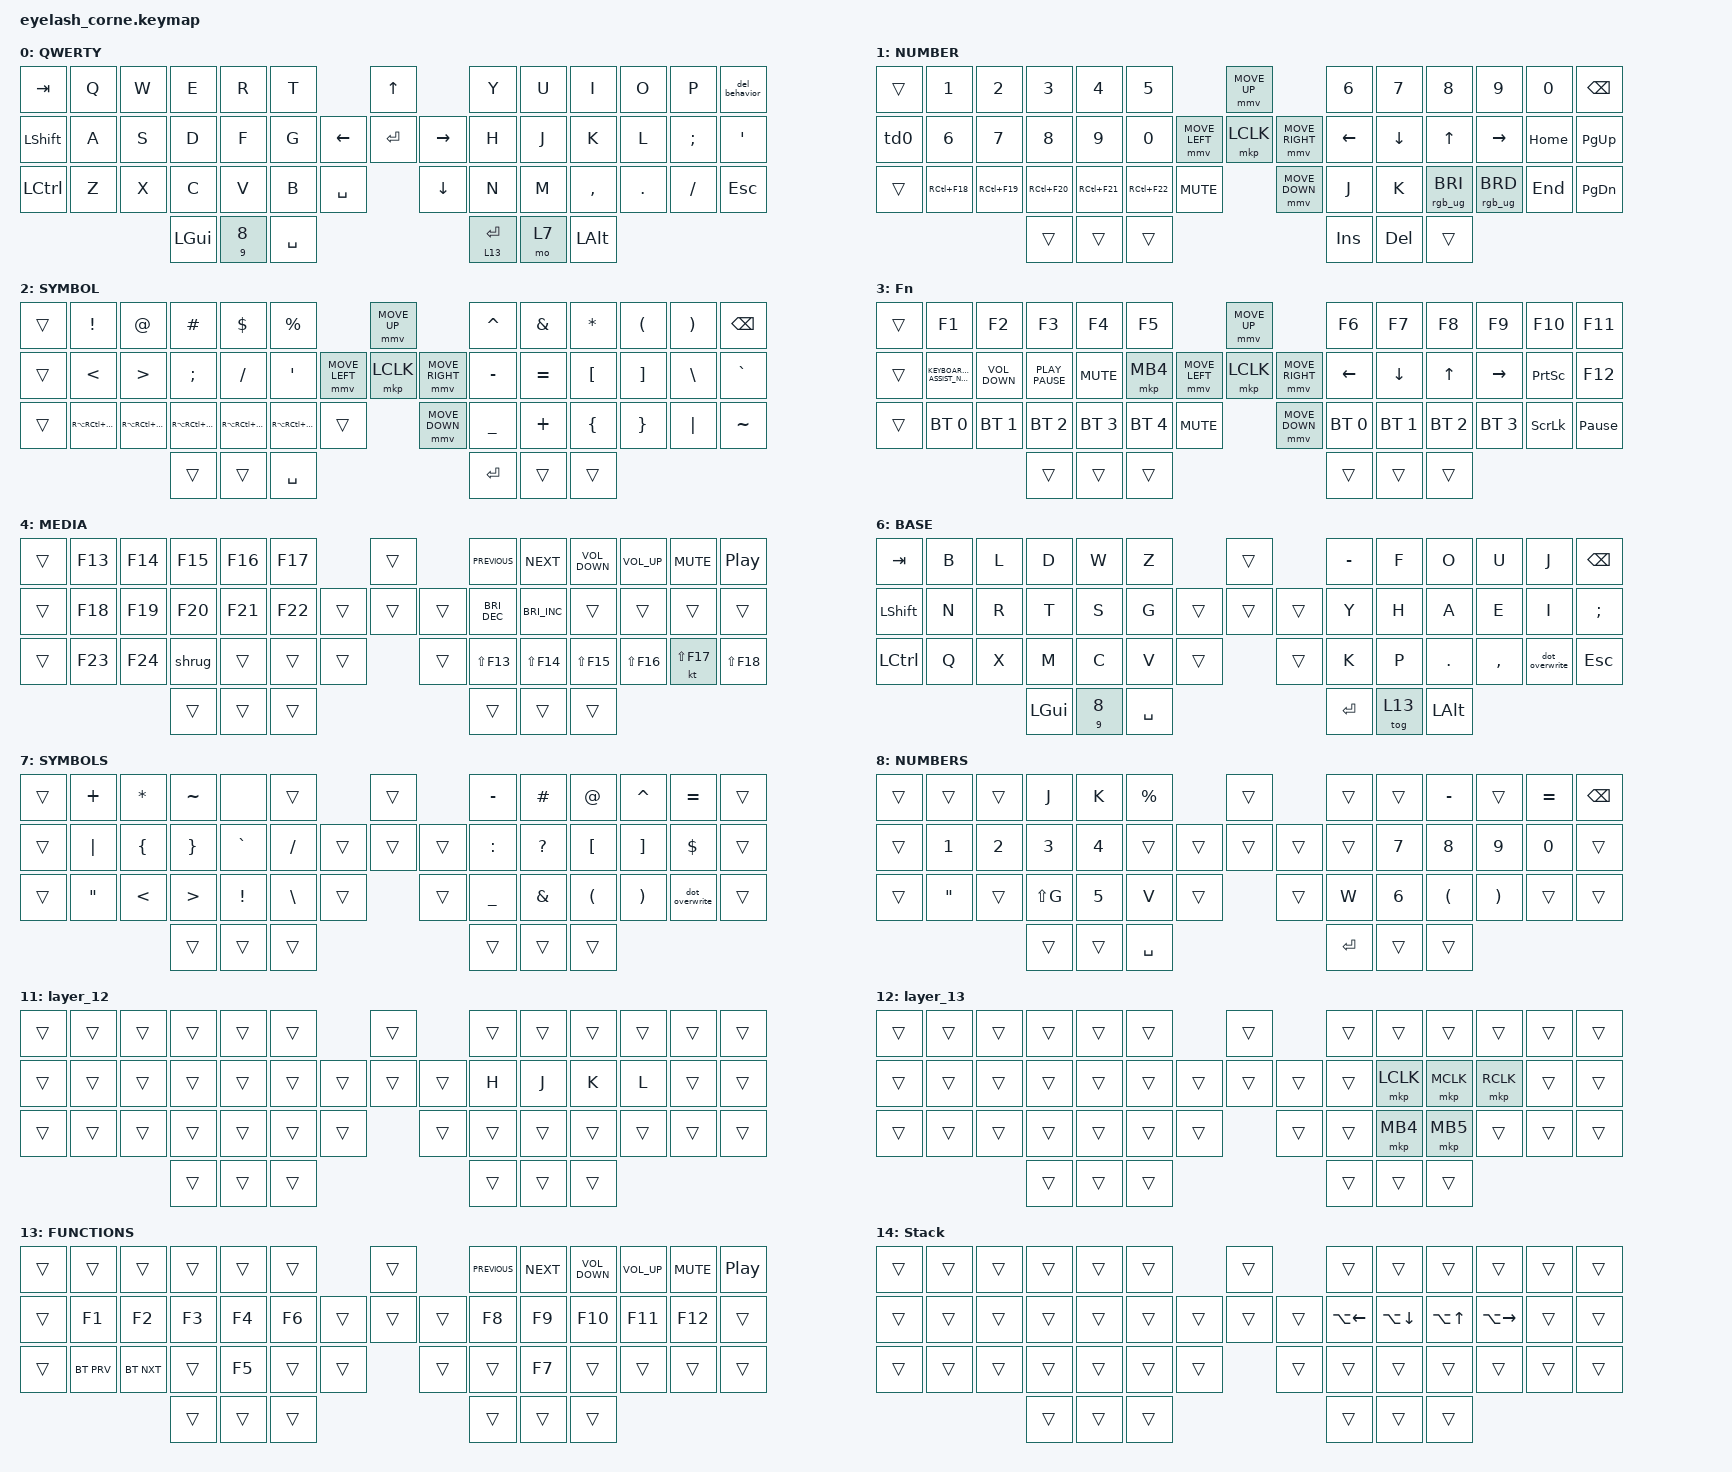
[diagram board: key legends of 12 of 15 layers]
#define ZMK_POINTING_DEFAULT_MOVE_VAL 1200
#define ZMK_POINTING_DEFAULT_SCRL_VAL 25

#include <input/processors.dtsi>
#include <zephyr/dt-bindings/input/input-event-codes.h>
#include <behaviors/num_word.dtsi>
#include <behaviors.dtsi>
#include <dt-bindings/zmk/bt.h>
#include <dt-bindings/zmk/keys.h>
#include <dt-bindings/zmk/outputs.h>
#include <dt-bindings/zmk/pointing.h>
#include <dt-bindings/zmk/rgb.h>

&mmv_input_listener { input-processors = <&zip_xy_scaler 2 1>; };

&msc_input_listener { input-processors = <&zip_scroll_scaler 2 1>; };

&msc {
    acceleration-exponent = <1>;      // 0
    time-to-max-speed-ms = <100>;       // 300
    delay-ms = <0>;                   // 0
};

&mmv {
    time-to-max-speed-ms = <500>;
    acceleration-exponent = <1>;
    trigger-period-ms = <16>;
};

&soft_off { hold-time-ms = <2000>; };

/ {
    behaviors {
        smart_num_nav: smart_num_nav {
            compatible = "zmk,behavior-hold-tap";
            #binding-cells = <2>;
            flavor = "tap-preferred";
            tapping-term-ms = <200>;
            bindings = <&nav_word>, <&num_word>;
            display-name = "Smart Num/Nav";
        };

        nav_word: nav_word {
            compatible = "zmk,behavior-auto-layer";
            #binding-cells = <1>;
            continue-list = <LEFT DOWN UP RIGHT PG_DN PG_UP HOME END>;
            ignore-modifiers;
        };

        win_word: win_word {
            compatible = "zmk,behavior-auto-layer";
            #binding-cells = <1>;
            continue-list = <
                SEMICOLON LEFT_BRACKET RIGHT_BRACKET
                O M
                N1 N2 N3 N4 N5 N6 N7 N8 N9
                H J K L T
                Q P I
                X Y
                MINUS PLUS
            >;
            ignore-modifiers;
        };

        td0: td0 {
            compatible = "zmk,behavior-tap-dance";
            display-name = "Shift/Caps Lock Tap Dance";
            #binding-cells = <0>;
            bindings = <&kp LEFT_SHIFT>, <&kp CAPS>;
        };

        del_behavior: del_behavior {
            compatible = "zmk,behavior-mod-morph";
            label = "DEL_BEHAVIOR";
            bindings = <&kp BACKSPACE>, <&kp DELETE>;

            #binding-cells = <0>;
            mods = <(MOD_LALT)>;
        };

        dot_overwrite: dot_overwrite {
            compatible = "zmk,behavior-mod-morph";
            label = "DOT_OVERWRITE";
            bindings = <&kp PERIOD>, <&kp COMMA>;

            #binding-cells = <0>;
            mods = <(MOD_LSFT)>;
        };
    };

    rgb_encoder: rgb_encoder {
        compatible = "zmk,behavior-sensor-rotate";
        #sensor-binding-cells = <0>;
        bindings = <&rgb_ug RGB_BRI>, <&rgb_ug RGB_BRD>;
    };

    scroll_encoder: scroll_encoder {
        compatible = "zmk,behavior-sensor-rotate";
        #sensor-binding-cells = <0>;
        bindings = <&msc SCRL_DOWN>, <&msc SCRL_UP>;

        tap-ms = <100>;
    };

    combos {
        compatible = "zmk,combos";

        softoff {
            bindings = <&soft_off>;
            key-positions = <1 15 29>;
        };

        caps_word_combo {
            bindings = <&caps_word>;
            key-positions = <43 46>;
            layers = <0 6>;
        };

        lpkt {
            bindings = <&kp LEFT_PARENTHESIS>;
            key-positions = <4 5>;
            layers = <0 6>;
        };

        lbrt {
            bindings = <&kp LEFT_BRACKET>;
            key-positions = <18 17>;
            layers = <0 6>;
        };

        lbrs {
            bindings = <&kp LEFT_BRACE>;
            key-positions = <33 32>;
            layers = <0 6>;
        };

        rpkt {
            bindings = <&kp RIGHT_PARENTHESIS>;
            key-positions = <7 8>;
            layers = <0 6>;
        };

        rbrt {
            bindings = <&kp RIGHT_BRACKET>;
            key-positions = <23 22>;
            layers = <0 6>;
        };

        rbrs {
            bindings = <&kp RIGHT_BRACE>;
            key-positions = <36 37>;
            layers = <0 6>;
        };

        to-5 {
            bindings = <&tog 5>;
            key-positions = <0 12>;
            layers = <0 6>;
        };

        to-6 {
            bindings = <&tog 0>;
            key-positions = <0 5 44>;
            layers = <0>;
        };

        qw_esc {
            bindings = <&kp ESC>;
            key-positions = <1 2>;
            layers = <0 6>;
        };

        sys_reset_left {
            bindings = <&sys_reset>;
            key-positions = <0 13>;
            layers = <5>;
        };

        bootloader_left {
            bindings = <&bootloader>;
            key-positions = <13 28>;
            layers = <5>;
        };

        studio_lock {
            bindings = <&studio_unlock>;
            key-positions = <0 28>;
            layers = <5>;
        };

        sys_reset_right {
            bindings = <&sys_reset>;
            key-positions = <12 27>;
            layers = <5>;
        };

        bootloader_right {
            bindings = <&bootloader>;
            key-positions = <12 41>;
            layers = <5>;
        };

        bt_clear {
            bindings = <&bt BT_CLR_ALL>;
            key-positions = <4 3 2>;
            layers = <5>;
        };

        bt_clear_curr {
            bindings = <&bt BT_CLR>;
            key-positions = <15 16 17>;
            layers = <5>;
        };

        new_q {
            bindings = <&kp Q>;
            key-positions = <2 3>;
            layers = <6 0>;
        };

        new_z {
            bindings = <&kp Z>;
            key-positions = <3 4>;
            layers = <6 0>;
        };

        new_del {
            bindings = <&kp DEL>;
            key-positions = <2 3 4>;
            layers = <6 0>;
        };

        gth {
            bindings = <&gth>;
            key-positions = <4 17>;
            layers = <6 0>;
        };

        lthc {
            bindings = <&lth>;
            key-positions = <17 32>;
            layers = <0 6>;
        };

        h_tagc {
            bindings = <&h_tag>;
            key-positions = <8 23>;
        };

        arrowc {
            bindings = <&arrow>;
            key-positions = <9 24>;
        };

        new_qwer {
            bindings = <&to 6>;
            key-positions = <0 5 33>;
            layers = <0>;
        };

        new_qwer_ret {
            bindings = <&to 0>;
            key-positions = <0 5 33>;
            layers = <6>;
        };

        to_win {
            bindings = <&win_word 10>;
            key-positions = <16 24>;
        };
    };

    macros {
        shrug: shrug {
            compatible = "zmk,behavior-macro";
            #binding-cells = <0>;
            wait-ms = <10>;
            tap-ms = <20>;
            bindings =
                <&macro_press>,
                <&kp LCTRL &kp LSHFT>,
                <&macro_tap>,
                <&kp U>,
                <&macro_release>,
                <&kp LCTRL &kp LSHFT>,
                <&macro_tap>,
                <&kp N0 &kp N0 &kp A &kp F &kp SPC>,
                <&macro_tap>,
                <&kp BACKSLASH>,
                <&macro_tap>,
                <&kp UNDER>,
                <&macro_tap>,
                <&kp LPAR>,
                <&macro_press>,
                <&kp LCTRL &kp LSHFT>,
                <&macro_tap>,
                <&kp U>,
                <&macro_release>,
                <&kp LCTRL &kp LSHFT>,
                <&macro_tap>,
                <&kp N3 &kp N0 &kp C &kp N4 &kp SPC>,
                <&macro_tap>,
                <&kp RPAR>,
                <&macro_tap>,
                <&kp UNDER>,
                <&macro_tap>,
                <&kp FSLH>,
                <&macro_press>,
                <&kp LCTRL &kp LSHFT>,
                <&macro_tap>,
                <&kp U>,
                <&macro_release>,
                <&kp LCTRL &kp LSHFT>,
                <&macro_tap>,
                <&kp N0 &kp N0 &kp A &kp F &kp SPC>;
        };

        gth: gth {
            compatible = "zmk,behavior-macro";
            #binding-cells = <0>;
            bindings = <&kp GT &kp EQUAL>;
            label = "GTH";
        };

        lth: lth {
            compatible = "zmk,behavior-macro";
            #binding-cells = <0>;
            bindings = <&kp LT &kp EQUAL>;
            label = "LTH";
        };

        arrow: arrow {
            compatible = "zmk,behavior-macro";
            #binding-cells = <0>;
            bindings = <&kp EQUAL &kp GT>;
            label = "ARROW";
        };

        h_tag: new_macro {
            compatible = "zmk,behavior-macro";
            #binding-cells = <0>;
            bindings = <&kp POUND>;
            label = "NEW_MACRO";
        };
    };

    keymap {
        compatible = "zmk,keymap";

        default_layer {
            display-name = "QWERTY";
            bindings = <
&kp TAB         &kp Q  &kp W  &kp E     &kp R        &kp T                             &kp UP                &kp Y         &kp U  &kp I         &kp O    &kp P     &del_behavior
&kp LEFT_SHIFT  &kp A  &kp S  &kp D     &kp F        &kp G                   &kp LEFT  &kp ENTER  &kp RIGHT  &kp H         &kp J  &kp K         &kp L    &kp SEMI  &kp SQT
&kp LCTRL       &kp Z  &kp X  &kp C     &kp V        &kp B      &kp SPACE              &kp DOWN              &kp N         &kp M  &kp COMMA     &kp DOT  &kp FSLH  &kp ESC
                              &kp LGUI  &smart_num_nav 9 8  &kp SPACE                                     &lt 13 ENTER  &mo 7  &kp LEFT_ALT
            >;

            sensor-bindings = <&inc_dec_kp C_VOLUME_UP C_VOL_DN>;
        };

        lower_layer {
            display-name = "NUMBER";
            bindings = <
&trans  &kp N1        &kp N2        &kp N3        &kp N4        &kp N5                                      &mmv MOVE_UP                     &kp N6    &kp N7    &kp N8           &kp N9           &kp N0    &kp BSPC
&td0    &kp NUMBER_6  &kp NUMBER_7  &kp NUMBER_8  &kp NUMBER_9  &kp NUMBER_0                &mmv MOVE_LEFT  &mkp LCLK       &mmv MOVE_RIGHT  &kp LEFT  &kp DOWN  &kp UP           &kp RIGHT        &kp HOME  &kp PG_UP
&trans  &kp RC(F18)   &kp RC(F19)   &kp RC(F20)   &kp RC(F21)   &kp RC(F22)   &kp C_MUTE                    &mmv MOVE_DOWN                   &kp J     &kp K     &rgb_ug RGB_BRI  &rgb_ug RGB_BRD  &kp END   &kp PG_DN
                                    &trans        &trans        &trans                                                                       &kp INS   &kp DEL   &trans
            >;

            sensor-bindings = <&scroll_encoder>;
        };

        raise_layer {
            display-name = "SYMBOL";
            bindings = <
&trans  &kp EXCL         &kp AT            &kp HASH         &kp DLLR         &kp PRCNT                                  &mmv MOVE_UP                     &kp CARET  &kp AMPS   &kp ASTRK  &kp LPAR  &kp RPAR  &kp BSPC
&trans  &kp LESS_THAN    &kp GREATER_THAN  &kp SEMICOLON    &kp SLASH        &kp SQT                    &mmv MOVE_LEFT  &mkp LCLK       &mmv MOVE_RIGHT  &kp MINUS  &kp EQUAL  &kp LBKT   &kp RBKT  &kp BSLH  &kp GRAVE
&trans  &kp RA(RC(F13))  &kp RA(RC(F14))   &kp RA(RC(F15))  &kp RA(RC(F16))  &kp RA(RC(F17))  &trans                    &mmv MOVE_DOWN                   &kp UNDER  &kp PLUS   &kp LBRC   &kp RBRC  &kp PIPE  &kp TILDE
                                           &trans           &trans           &kp SPACE                                                                   &kp RET    &trans     &trans
            >;

            sensor-bindings = <&scroll_encoder>;
        };

        layer_3 {
            display-name = "Fn";
            bindings = <
&trans  &kp F1                            &kp F2             &kp F3            &kp F4        &kp F5                                      &mmv MOVE_UP                     &kp F6        &kp F7        &kp F8        &kp F9        &kp F10          &kp F11
&trans  &kp C_KEYBOARD_INPUT_ASSIST_NEXT  &kp K_VOLUME_DOWN  &kp K_PLAY_PAUSE  &kp K_MUTE    &mkp MB4                    &mmv MOVE_LEFT  &mkp LCLK       &mmv MOVE_RIGHT  &kp LEFT      &kp DOWN      &kp UP        &kp RIGHT     &kp PRINTSCREEN  &kp F12
&trans  &bt BT_SEL 0                      &bt BT_SEL 1       &bt BT_SEL 2      &bt BT_SEL 3  &bt BT_SEL 4  &kp C_MUTE                    &mmv MOVE_DOWN                   &bt BT_SEL 0  &bt BT_SEL 1  &bt BT_SEL 2  &bt BT_SEL 3  &kp SCROLLLOCK   &kp PAUSE_BREAK
                                                             &trans            &trans        &trans                                                                       &trans        &trans        &trans
            >;

            sensor-bindings = <&scroll_encoder>;
        };

        layer_5 {
            bindings = <
&trans  &kp F13  &kp F14  &kp F15  &kp F16  &kp F17                    &trans          &kp C_PREVIOUS        &kp C_NEXT            &kp C_VOLUME_DOWN  &kp C_VOLUME_UP  &kp C_MUTE   &kp C_PLAY_PAUSE
&trans  &kp F18  &kp F19  &kp F20  &kp F21  &kp F22            &trans  &trans  &trans  &kp C_BRIGHTNESS_DEC  &kp C_BRIGHTNESS_INC  &trans             &trans           &trans       &trans
&trans  &kp F23  &kp F24  &shrug   &trans   &trans   &trans            &trans          &kp LS(F13)           &kp LS(F14)           &kp LS(F15)        &kp LS(F16)      &kt LS(F17)  &kp LS(F18)
                          &trans   &trans   &trans                                     &trans                &trans                &trans
            >;

            label = "MEDIA";
        };

        BT {
            bindings = <
&out OUT_TOG                      &bt BT_PRV       &bt BT_NXT       &none            &none            &none                            &none         &none  &none         &none         &none         &none         &none
&rgb_ug RGB_COLOR_HSB(256,64,46)  &rgb_ug RGB_BRD  &rgb_ug RGB_BRI  &rgb_ug RGB_SPD  &rgb_ug RGB_SPI  &rgb_ug RGB_EFF           &none  &none  &none  &none  &bt BT_SEL 1  &bt BT_SEL 2  &bt BT_SEL 3  &bt BT_SEL 4  &none
&rgb_ug RGB_COLOR_HSB(202,73,53)  &rgb_ug RGB_TOG  &rgb_ug RGB_HUI  &rgb_ug RGB_HUD  &rgb_ug RGB_SAI  &rgb_ug RGB_SAD  &none           &none         &none  &bt BT_SEL 0  &none         &none         &none         &tog 5
                                                                    &none            &none            &none                                          &none  &none         &none
            >;

            label = "BT";
        };

        new_base {
            bindings = <
&kp TAB    &kp B  &kp L  &kp D     &kp W  &kp Z                        &trans          &kp MINUS  &kp F    &kp O     &kp U      &kp J           &kp BSPC
&kp LSHFT  &kp N  &kp R  &kp T     &kp S  &kp G                &trans  &trans  &trans  &kp Y      &kp H    &kp A     &kp E      &kp I           &kp SEMI
&kp LCTRL  &kp Q  &kp X  &kp M     &kp C  &kp V      &trans            &trans          &kp K      &kp P    &kp DOT   &kp COMMA  &dot_overwrite  &kp ESC
                         &kp LGUI  &smart_num_nav 9 8  &kp SPACE                         &kp ENTER  &tog 13  &kp LALT
            >;

            label = "BASE";
        };

        sym_new {
            bindings = <
&trans  &kp PLUS           &kp ASTERISK  &kp TILDE  &none      &trans                           &trans          &kp MINUS       &kp HASH   &kp AT    &kp CARET          &kp EQUAL       &trans
&trans  &kp PIPE           &kp LBRC      &kp RBRC   &kp GRAVE  &kp SLASH                &trans  &trans  &trans  &kp COLON       &kp QMARK  &kp LBKT  &kp RIGHT_BRACKET  &kp DLLR        &trans
&trans  &kp DOUBLE_QUOTES  &kp LT        &kp GT     &kp EXCL   &kp BACKSLASH  &trans            &trans          &kp UNDERSCORE  &kp AMPS   &kp LPAR  &kp RPAR           &dot_overwrite  &trans
                                         &trans     &trans     &trans                                           &trans          &trans     &trans
            >;

            label = "SYMBOLS";
        };

        numbers_new {
            bindings = <
&trans  &trans             &trans  &kp J      &kp K   &kp PERCENT                    &trans          &trans     &trans  &kp MINUS             &trans                 &kp EQUAL  &kp BACKSPACE
&trans  &kp N1             &kp N2  &kp N3     &kp N4  &trans                 &trans  &trans  &trans  &trans     &kp N7  &kp N8                &kp N9                 &kp N0     &trans
&trans  &kp DOUBLE_QUOTES  &trans  &kp LS(G)  &kp N5  &kp V        &trans            &trans          &kp W      &kp N6  &kp LEFT_PARENTHESIS  &kp RIGHT_PARENTHESIS  &trans     &trans
                                   &trans     &trans  &kp SPACE                                      &kp ENTER  &trans  &trans
            >;

            label = "NUMBERS";
        };

        navigation {
            bindings = <
&trans  &kp LC(D)               &kp LC(F)  &kp LC(C)        &kp LC(V)    &trans                    &trans          &trans    &kp END    &kp HOME   &trans     &trans  &trans
&trans  &mt (LEFT_SHIFT) LC(A)  &mkp RCLK  &mkp MCLK        &mkp LCLK    &trans            &trans  &trans  &trans  &kp LEFT  &kp DOWN   &kp UP     &kp RIGHT  &trans  &trans
&trans  &trans                  &trans     &kp LC(LS(TAB))  &kp LC(TAB)  &trans  &trans            &trans          &trans    &kp PG_DN  &kp PG_UP  &trans     &trans  &trans
                                           &trans           &trans       &trans                                    &trans    &trans     &trans
            >;

            label = "NAV";
        };

        win_manager {
            bindings = <
&trans  &trans                         &kp LA(SEMICOLON)                    &mt (LA(LS(LEFT_BRACKET))) LA(LEFT_BRACKET)   &mt (LA(LS(RIGHT_BRACKET))) LA(RIGHT_BRACKET)  &trans  &trans  &trans  &mt (LA(LS(O))) LA(O)  &mt (LA(LS(M))) LA(M)  &trans                  &trans                     &trans
&trans  &mt (LA(LS(N1))) LA(NUMBER_1)  &mt (LA(LS(N2))) LA(NUMBER_2)        &mt (LA(LS(N3))) LA(NUMBER_3)                  &mt (LA(LS(N4))) LA(NUMBER_4)                  &mt (LS(LA(N9))) LA(N9)  &trans  &trans  &trans  &mt (LS(LA(H))) LA(H)  &mt (LA(LS(J))) LA(J)  &mt (LA(LS(K))) LA(K)  &mt (LA(LS(L))) LA(L)  &mt (LA(LS(F))) LA(T)  &trans
&trans  &mt (LA(LS(N5))) LA(N5)        &mt (LA(LS(NUMBER_6))) LA(NUMBER_6)  &mt (LA(LS(N7))) LA(N7)                        &mt (LA(LS(N8))) LA(N8)                        &trans                   &trans            &trans          &trans                 &mt (LA(LS(R))) LA(Q)  &mt (LA(MINUS)) LA(X)  &mt (LA(PLUS)) LA(Y)    &mt (LA(I)) LA(P)      &trans
                                                                            &trans                         &mo 14                         &trans                                                     &trans                 &trans                     &trans
            >;

            label = "MANAGER";
        };

        layer_12 {
            bindings = <
&trans  &trans  &trans  &trans  &trans  &trans                    &trans          &trans  &trans  &trans  &trans  &trans  &trans
&trans  &trans  &trans  &trans  &trans  &trans            &trans  &trans  &trans  &kp H   &kp J   &kp K   &kp L   &trans  &trans
&trans  &trans  &trans  &trans  &trans  &trans  &trans            &trans          &trans  &trans  &trans  &trans  &trans  &trans
                        &trans  &trans  &trans                                    &trans  &trans  &trans
            >;
        };

        layer_13 {
            bindings = <
&trans  &trans  &trans  &trans  &trans  &trans                    &trans          &trans  &trans     &trans     &trans     &trans  &trans
&trans  &trans  &trans  &trans  &trans  &trans            &trans  &trans  &trans  &trans  &mkp LCLK  &mkp MCLK  &mkp RCLK  &trans  &trans
&trans  &trans  &trans  &trans  &trans  &trans  &trans            &trans          &trans  &mkp MB4   &mkp MB5   &trans     &trans  &trans
                        &trans  &trans  &trans                                    &trans  &trans     &trans
            >;
        };

        new_fn {
            bindings = <
&trans  &trans      &trans      &trans  &trans  &trans                    &trans          &kp C_PREVIOUS  &kp C_NEXT  &kp C_VOLUME_DOWN  &kp C_VOLUME_UP  &kp C_MUTE  &kp C_PLAY_PAUSE
&trans  &kp F1      &kp F2      &kp F3  &kp F4  &kp F6            &trans  &trans  &trans  &kp F8          &kp F9      &kp F10            &kp F11          &kp F12     &trans
&trans  &bt BT_PRV  &bt BT_NXT  &trans  &kp F5  &trans  &trans            &trans          &trans          &kp F7      &trans             &trans           &trans      &trans
                                &trans  &trans  &trans                                    &trans          &trans      &trans
            >;

            label = "FUNCTIONS";
        };

        WinStack {
            bindings = <
&trans  &trans  &trans  &trans  &trans  &trans                    &trans          &trans        &trans        &trans      &trans         &trans  &trans
&trans  &trans  &trans  &trans  &trans  &trans            &trans  &trans  &trans  &kp LA(LEFT)  &kp LA(DOWN)  &kp LA(UP)  &kp LA(RIGHT)  &trans  &trans
&trans  &trans  &trans  &trans  &trans  &trans  &trans            &trans          &trans        &trans        &trans      &trans         &trans  &trans
                        &trans  &trans  &trans                                    &trans        &trans        &trans
            >;

            label = "Stack";
        };
    };
};
